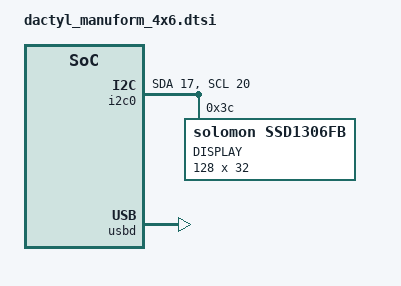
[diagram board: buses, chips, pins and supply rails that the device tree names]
#include <dt-bindings/zmk/matrix_transform.h>

/ {
    chosen {
        zmk,kscan = &kscan0;
        zmk,matrix_transform = &default_transform;
        zephyr,console = &cdc_acm_uart;
    };

    default_transform: keymap_transform_0 {
        compatible = "zmk,matrix-transform";
        columns = <12>;
        rows = <5>;

        map = <
                                                     RC(0,0)
RC(0,1) RC(0,2) 
        >;
    };


};

&i2c0 {
    status = "okay";
    sda-pin = <17>;
    scl-pin = <20>; 

    oled: ssd1306@3c {
        compatible = "solomon,ssd1306fb";
        reg = <0x3c>;
        label = "DISPLAY";
        width = <128>;
        height = <32>;
        segment-offset = <0>;
        page-offset = <0>;
        display-offset = <0>;
        multiplex-ratio = <31>;
        segment-remap;
        com-invdir;
        com-sequential;
        prechargep = <0x22>;
    };
};

&usbd {
  status = "okay";
  cdc_acm_uart: cdc_acm_uart {
    compatible = "zephyr,cdc-acm-uart";
    label = "CDC_ACM_0";
  };
};
